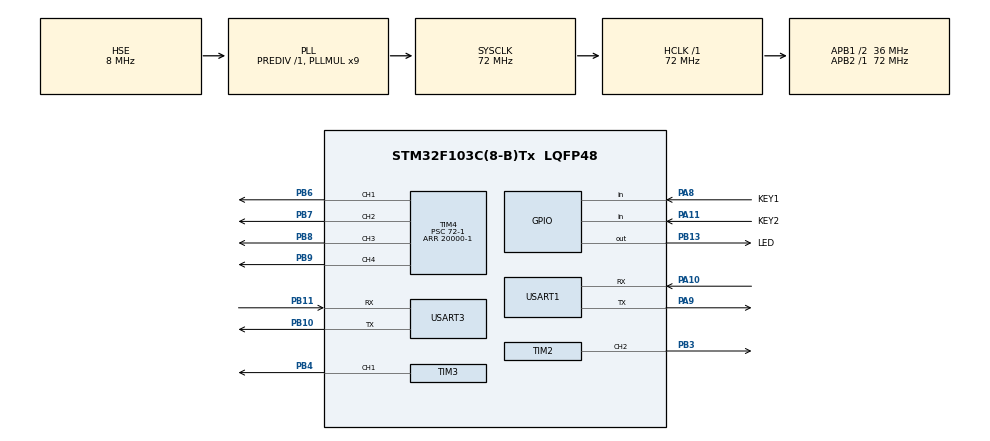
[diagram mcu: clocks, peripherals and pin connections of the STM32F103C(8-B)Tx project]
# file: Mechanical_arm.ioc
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Dma.Request0=USART1_RX
Dma.Request1=USART1_TX
Dma.Request2=USART3_RX
Dma.Request3=USART3_TX
Dma.USART1_RX.0.Direction=DMA_PERIPH_TO_MEMORY
Dma.USART1_RX.0.Instance=DMA1_Channel5
Dma.USART1_RX.0.MemDataAlignment=DMA_MDATAALIGN_BYTE
Dma.USART1_RX.0.MemInc=DMA_MINC_ENABLE
Dma.USART1_RX.0.Mode=DMA_NORMAL
Dma.USART1_RX.0.PeriphDataAlignment=DMA_PDATAALIGN_BYTE
Dma.USART1_RX.0.PeriphInc=DMA_PINC_DISABLE
Dma.USART1_RX.0.Priority=DMA_PRIORITY_HIGH
Dma.USART1_TX.1.Direction=DMA_MEMORY_TO_PERIPH
Dma.USART1_TX.1.Instance=DMA1_Channel4
Dma.USART1_TX.1.MemDataAlignment=DMA_MDATAALIGN_BYTE
Dma.USART1_TX.1.MemInc=DMA_MINC_ENABLE
Dma.USART1_TX.1.Mode=DMA_NORMAL
Dma.USART1_TX.1.PeriphDataAlignment=DMA_PDATAALIGN_BYTE
Dma.USART1_TX.1.PeriphInc=DMA_PINC_DISABLE
Dma.USART1_TX.1.Priority=DMA_PRIORITY_HIGH
Dma.USART3_RX.2.Direction=DMA_PERIPH_TO_MEMORY
Dma.USART3_RX.2.Instance=DMA1_Channel3
Dma.USART3_RX.2.MemDataAlignment=DMA_MDATAALIGN_BYTE
Dma.USART3_RX.2.MemInc=DMA_MINC_ENABLE
Dma.USART3_RX.2.Mode=DMA_NORMAL
Dma.USART3_RX.2.PeriphDataAlignment=DMA_PDATAALIGN_BYTE
Dma.USART3_RX.2.PeriphInc=DMA_PINC_DISABLE
Dma.USART3_RX.2.Priority=DMA_PRIORITY_HIGH
Dma.USART3_TX.3.Direction=DMA_MEMORY_TO_PERIPH
Dma.USART3_TX.3.Instance=DMA1_Channel2
Dma.USART3_TX.3.MemDataAlignment=DMA_MDATAALIGN_BYTE
Dma.USART3_TX.3.MemInc=DMA_MINC_ENABLE
Dma.USART3_TX.3.Mode=DMA_NORMAL
Dma.USART3_TX.3.PeriphDataAlignment=DMA_PDATAALIGN_BYTE
Dma.USART3_TX.3.PeriphInc=DMA_PINC_DISABLE
Dma.USART3_TX.3.Priority=DMA_PRIORITY_HIGH
FREERTOS.BinarySemaphores01=UART_RX_Finsh,Dynamic,NULL;Servo_Control,Dynamic,NULL
FREERTOS.Queues01=Servo_Tx_Queue,8,8,1,Dynamic,NULL,NULL
FREERTOS.Tasks01=defaultTask,24,128,StartDefaultTask,Default,NULL,Dynamic,NULL,NULL;Servo_Task,47,128,Servo_Task_Fun,As weak,NULL,Dynamic,NULL,NULL;USART1_RX_Task,54,128,USART1_RX_Task_Fun,As weak,NULL,Dynamic,NULL,NULL;Servo_data_uplo,8,128,Servo_data_upload_Fun,As weak,NULL,Dynamic,NULL,NULL;servoRotateTask,48,128,servoRotateTask_Fun,As weak,NULL,Dynamic,NULL,NULL
FREERTOS.Timers01=LED_Timer0,LED_Timer0_Callback,osTimerPeriodic,Default,NULL,Dynamic,NULL
FREERTOS.configTOTAL_HEAP_SIZE=5120
Mcu.Family=STM32F1
Mcu.Name=STM32F103C(8-B)Tx
Mcu.Package=LQFP48
NVIC.DMA1_Channel2_IRQn=true\:5\:0\:false\:false\:true\:true\:false\:true\:true
NVIC.DMA1_Channel3_IRQn=true\:5\:0\:false\:false\:true\:true\:false\:true\:true
NVIC.DMA1_Channel4_IRQn=true\:5\:0\:false\:false\:true\:true\:false\:true\:true
NVIC.DMA1_Channel5_IRQn=true\:5\:0\:false\:false\:true\:true\:false\:true\:true
NVIC.PriorityGroup=NVIC_PRIORITYGROUP_4
NVIC.USART1_IRQn=true\:5\:0\:false\:false\:true\:true\:true\:true\:true
NVIC.USART3_IRQn=true\:5\:0\:false\:false\:true\:true\:true\:true\:true
PA10.Mode=Asynchronous
PA10.Signal=USART1_RX
PA11.GPIO_Label=KEY2
PA11.Signal=GPIO_Input
PA13.Mode=Serial_Wire
PA13.Signal=SYS_JTMS-SWDIO
PA14.Mode=Serial_Wire
PA14.Signal=SYS_JTCK-SWCLK
PA8.GPIO_Label=KEY1
PA8.Signal=GPIO_Input
PA9.Mode=Asynchronous
PA9.Signal=USART1_TX
PB10.Mode=Asynchronous
PB10.Signal=USART3_TX
PB11.Mode=Asynchronous
PB11.Signal=USART3_RX
PB13.GPIO_Label=LED
PB13.Signal=GPIO_Output
PB3.Signal=S_TIM2_CH2
PB4.Signal=S_TIM3_CH1
PB6.Signal=S_TIM4_CH1
PB7.Signal=S_TIM4_CH2
PB8.Signal=S_TIM4_CH3
PB9.Signal=S_TIM4_CH4
PD0-OSC_IN.Mode=HSE-External-Oscillator
PD0-OSC_IN.Signal=RCC_OSC_IN
PD1-OSC_OUT.Mode=HSE-External-Oscillator
PD1-OSC_OUT.Signal=RCC_OSC_OUT
ProjectManager.HeapSize=0x400
ProjectManager.StackSize=0x800
ProjectManager.TargetToolchain=MDK-ARM V5.32
RCC.AHBFreq_Value=72000000
RCC.APB1CLKDivider=RCC_HCLK_DIV2
RCC.APB1Freq_Value=36000000
RCC.APB1TimFreq_Value=72000000
RCC.APB2Freq_Value=72000000
RCC.APB2TimFreq_Value=72000000
RCC.HCLKFreq_Value=72000000
RCC.PLLMUL=RCC_PLL_MUL9
RCC.PLLSourceVirtual=RCC_PLLSOURCE_HSE
RCC.SYSCLKFreq_VALUE=72000000
RCC.SYSCLKSource=RCC_SYSCLKSOURCE_PLLCLK
RCC.USBFreq_Value=72000000
SH.S_TIM2_CH2.0=TIM2_CH2,PWM Generation2 CH2
SH.S_TIM3_CH1.0=TIM3_CH1,PWM Generation1 CH1
SH.S_TIM4_CH1.0=TIM4_CH1,PWM Generation1 CH1
SH.S_TIM4_CH2.0=TIM4_CH2,PWM Generation2 CH2
SH.S_TIM4_CH3.0=TIM4_CH3,PWM Generation3 CH3
SH.S_TIM4_CH4.0=TIM4_CH4,PWM Generation4 CH4
TIM2.AutoReloadPreload=TIM_AUTORELOAD_PRELOAD_ENABLE
TIM2.Channel-PWM\ Generation2\ CH2=TIM_CHANNEL_2
TIM2.Period=20000-1
TIM2.Prescaler=72-1
TIM3.AutoReloadPreload=TIM_AUTORELOAD_PRELOAD_ENABLE
TIM3.Channel-PWM\ Generation1\ CH1=TIM_CHANNEL_1
TIM3.Period=20000-1
TIM3.Prescaler=72-1
TIM4.AutoReloadPreload=TIM_AUTORELOAD_PRELOAD_ENABLE
TIM4.Channel-PWM\ Generation1\ CH1=TIM_CHANNEL_1
TIM4.Channel-PWM\ Generation2\ CH2=TIM_CHANNEL_2
TIM4.Channel-PWM\ Generation3\ CH3=TIM_CHANNEL_3
TIM4.Channel-PWM\ Generation4\ CH4=TIM_CHANNEL_4
TIM4.Period=20000-1
TIM4.Prescaler=72-1
USART1.VirtualMode=VM_ASYNC
USART3.VirtualMode=VM_ASYNC
VP_FREERTOS_VS_CMSIS_V2.Mode=CMSIS_V2
VP_TIM2_VS_ClockSourceINT.Mode=Internal
VP_TIM3_VS_ClockSourceINT.Mode=Internal
VP_TIM4_VS_ClockSourceINT.Mode=Internal
board=custom

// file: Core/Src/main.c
/* USER CODE BEGIN Header */
/**
 ******************************************************************************
 * @file           : main.c
 * @brief          : Main program body
 ******************************************************************************
 * @attention
 *
 * Copyright (c) 2023 STMicroelectronics.
 * All rights reserved.
 *
 * This software is licensed under terms that can be found in the LICENSE file
 * in the root directory of this software component.
 * If no LICENSE file comes with this software, it is provided AS-IS.
 *
 ******************************************************************************
 */
/* USER CODE END Header */
#include "main.h"
#include "cmsis_os.h"
#include "dma.h"
#include "gpio.h"
#include "tim.h"
#include "usart.h"

/* USER CODE BEGIN Includes */
#include "Servo.h"
#include "UART.h"
/* USER CODE END Includes */

void SystemClock_Config(void);
void MX_FREERTOS_Init(void);

int main(void)
{

    /* MCU Configuration--------------------------------------------------------*/

    /* Reset of all peripherals, Initializes the Flash interface and the Systick. */
    HAL_Init();

    /* Configure the system clock */
    SystemClock_Config();

    /* Initialize all configured peripherals */
    MX_GPIO_Init();
    MX_DMA_Init();
    MX_TIM2_Init();
    MX_TIM3_Init();
    MX_TIM4_Init();
    MX_USART1_UART_Init();
    MX_USART3_UART_Init();
    /* USER CODE BEGIN 2 */

    Servo_Init();

//    UART1_Start_Receive();
//    UART3_Start_Receive();
//    uart_printf(&huart3, "+++");
//    UART3_Start_Receive();
//    uart_printf(&huart3, "AT+CWJAP=\"npi\",\"12345678\"");
//    UART3_Start_Receive();
//    uart_printf(&huart3, "AT+SAVETRANSLINK=1,\"192.168.12.1\",8080,\"TCP\"\r\n");

    debug("Init ok!\r\n");
    /* USER CODE END 2 */

    /* Init scheduler */
    osKernelInitialize(); /* Call init function for freertos objects (in freertos.c) */
    MX_FREERTOS_Init();

    /* Start scheduler */
    osKernelStart();

    /* We should never get here as control is now taken by the scheduler */
    /* Infinite loop */
    while (1)
    {

    }
}

void SystemClock_Config(void)
{
    RCC_OscInitTypeDef RCC_OscInitStruct = {0};
    RCC_ClkInitTypeDef RCC_ClkInitStruct = {0};

    /** Initializes the RCC Oscillators according to the specified parameters
     * in the RCC_OscInitTypeDef structure.
     */
    RCC_OscInitStruct.OscillatorType = RCC_OSCILLATORTYPE_HSE;
    RCC_OscInitStruct.HSEState = RCC_HSE_ON;
    RCC_OscInitStruct.HSEPredivValue = RCC_HSE_PREDIV_DIV1;
    RCC_OscInitStruct.HSIState = RCC_HSI_ON;
    RCC_OscInitStruct.PLL.PLLState = RCC_PLL_ON;
    RCC_OscInitStruct.PLL.PLLSource = RCC_PLLSOURCE_HSE;
    RCC_OscInitStruct.PLL.PLLMUL = RCC_PLL_MUL9;
    if (HAL_RCC_OscConfig(&RCC_OscInitStruct) != HAL_OK)
    {
        Error_Handler();
    }

    /** Initializes the CPU, AHB and APB buses clocks
     */
    RCC_ClkInitStruct.ClockType = RCC_CLOCKTYPE_HCLK | RCC_CLOCKTYPE_SYSCLK | RCC_CLOCKTYPE_PCLK1 | RCC_CLOCKTYPE_PCLK2;
    RCC_ClkInitStruct.SYSCLKSource = RCC_SYSCLKSOURCE_PLLCLK;
    RCC_ClkInitStruct.AHBCLKDivider = RCC_SYSCLK_DIV1;
    RCC_ClkInitStruct.APB1CLKDivider = RCC_HCLK_DIV2;
    RCC_ClkInitStruct.APB2CLKDivider = RCC_HCLK_DIV1;

    if (HAL_RCC_ClockConfig(&RCC_ClkInitStruct, FLASH_LATENCY_2) != HAL_OK)
    {
        Error_Handler();
    }
}

void Error_Handler(void)
{
    __disable_irq();
    while (1)
    {
    }
}

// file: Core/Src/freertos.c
/* USER CODE BEGIN Header */
/**
 ******************************************************************************
 * File Name          : freertos.c
 * Description        : Code for freertos applications
 ******************************************************************************
 * @attention
 *
 * Copyright (c) 2023 STMicroelectronics.
 * All rights reserved.
 *
 * This software is licensed under terms that can be found in the LICENSE file
 * in the root directory of this software component.
 * If no LICENSE file comes with this software, it is provided AS-IS.
 *
 ******************************************************************************
 */
/* USER CODE END Header */

#include "FreeRTOS.h"
#include "cmsis_os.h"
#include "main.h"
#include "task.h"

/* USER CODE BEGIN Includes */
#include "UART.h"
#include "app.h"
/* USER CODE END Includes */

/* USER CODE BEGIN Variables */
extern UART_HandleTypeDef huart1;
/* USER CODE END Variables */
/* Definitions for defaultTask */
osThreadId_t defaultTaskHandle;
const osThreadAttr_t defaultTask_attributes = {
    .name = "defaultTask",
    .stack_size = 128 * 4,
    .priority = (osPriority_t)osPriorityNormal,
};
/* Definitions for Servo_Task */
osThreadId_t Servo_TaskHandle;
const osThreadAttr_t Servo_Task_attributes = {
    .name = "Servo_Task",
    .stack_size = 128 * 4,
    .priority = (osPriority_t)osPriorityHigh7,
};
/* Definitions for USART1_RX_Task */
osThreadId_t USART1_RX_TaskHandle;
const osThreadAttr_t USART1_RX_Task_attributes = {
    .name = "USART1_RX_Task",
    .stack_size = 128 * 4,
    .priority = (osPriority_t)osPriorityRealtime6,
};
/* Definitions for Servo_data_uplo */
osThreadId_t Servo_data_uploHandle;
const osThreadAttr_t Servo_data_uplo_attributes = {
    .name = "Servo_data_uplo",
    .stack_size = 128 * 4,
    .priority = (osPriority_t)osPriorityLow,
};
/* Definitions for servoRotateTask */
osThreadId_t servoRotateTaskHandle;
const osThreadAttr_t servoRotateTask_attributes = {
    .name = "servoRotateTask",
    .stack_size = 128 * 4,
    .priority = (osPriority_t)osPriorityRealtime,
};
/* Definitions for Servo_Tx_Queue */
osMessageQueueId_t Servo_Tx_QueueHandle;
const osMessageQueueAttr_t Servo_Tx_Queue_attributes = {.name = "Servo_Tx_Queue"};
/* Definitions for LED_Timer0 */
osTimerId_t LED_Timer0Handle;
const osTimerAttr_t LED_Timer0_attributes = {.name = "LED_Timer0"};
/* Definitions for UART_RX_Finsh */
osSemaphoreId_t UART_RX_FinshHandle;
const osSemaphoreAttr_t UART_RX_Finsh_attributes = {.name = "UART_RX_Finsh"};
/* Definitions for Servo_Control */
osSemaphoreId_t Servo_ControlHandle;
const osSemaphoreAttr_t Servo_Control_attributes = {.name = "Servo_Control"};

void StartDefaultTask(void *argument);
void Servo_Task_Fun(void *argument);
void USART1_RX_Task_Fun(void *argument);
void Servo_data_upload_Fun(void *argument);
void servoRotateTask_Fun(void *argument);
void LED_Timer0_Callback(void *argument);

void MX_FREERTOS_Init(void); /* (MISRA C 2004 rule 8.1) */

void MX_FREERTOS_Init(void)
{

    /* Create the semaphores(s) */
    /* creation of UART_RX_Finsh */
    UART_RX_FinshHandle = osSemaphoreNew(1, 0, &UART_RX_Finsh_attributes);

    /* creation of Servo_Control */
    Servo_ControlHandle = osSemaphoreNew(1, 0, &Servo_Control_attributes);

    /* Create the timer(s) */
    /* creation of LED_Timer0 */
    LED_Timer0Handle = osTimerNew(LED_Timer0_Callback, osTimerPeriodic, NULL, &LED_Timer0_attributes);

    /* Create the queue(s) */
    /* creation of Servo_Tx_Queue */
    Servo_Tx_QueueHandle = osMessageQueueNew(10, 4, &Servo_Tx_Queue_attributes);

    /* Create the thread(s) */
    /* creation of defaultTask */
    defaultTaskHandle = osThreadNew(StartDefaultTask, NULL, &defaultTask_attributes);

    /* creation of Servo_Task */
    Servo_TaskHandle = osThreadNew(Servo_Task_Fun, NULL, &Servo_Task_attributes);

    /* creation of USART1_RX_Task */
    USART1_RX_TaskHandle = osThreadNew(USART1_RX_Task_Fun, NULL, &USART1_RX_Task_attributes);

    /* creation of Servo_data_uplo */
    Servo_data_uploHandle = osThreadNew(Servo_data_upload_Fun, NULL, &Servo_data_uplo_attributes);

    /* creation of servoRotateTask */
    servoRotateTaskHandle = osThreadNew(servoRotateTask_Fun, NULL, &servoRotateTask_attributes);

}

void StartDefaultTask(void *argument)
{
    /* USER CODE BEGIN StartDefaultTask */
    /* Infinite loop */

    osTimerStart(LED_Timer0Handle, 500);
    for (;;)
    {
        osDelay(1);
    }

    /* USER CODE END StartDefaultTask */
}

__weak void Servo_Task_Fun(void *argument)
{
    for (;;)
    {
        osDelay(1);
    }
}

__weak void USART1_RX_Task_Fun(void *argument)
{
    for (;;)
    {
        osDelay(1);
    }
}

__weak void Servo_data_upload_Fun(void *argument)
{
    for (;;)
    {
        osDelay(1);
    }
}

__weak void servoRotateTask_Fun(void *argument)
{
    for (;;)
    {
        osDelay(1);
    }
}

/* LED_Timer0_Callback function */
void LED_Timer0_Callback(void *argument)
{
    /* USER CODE BEGIN LED_Timer0_Callback */
    HAL_GPIO_TogglePin(LED_GPIO_Port, LED_Pin);

    /* USER CODE END LED_Timer0_Callback */
}
